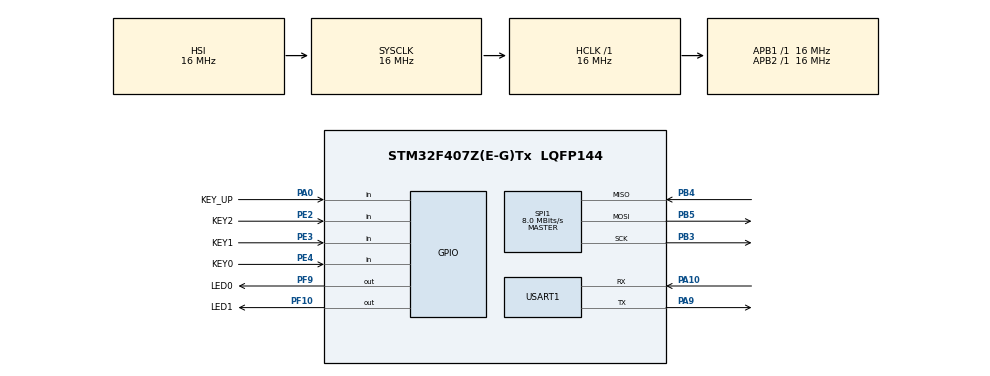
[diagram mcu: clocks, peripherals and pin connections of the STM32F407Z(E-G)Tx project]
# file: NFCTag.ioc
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Mcu.Family=STM32F4
Mcu.Name=STM32F407Z(E-G)Tx
Mcu.Package=LQFP144
NVIC.PriorityGroup=NVIC_PRIORITYGROUP_4
PA0-WKUP.GPIO_Label=KEY_UP
PA0-WKUP.GPIO_PuPd=GPIO_PULLDOWN
PA0-WKUP.Signal=GPIO_Input
PA10.Mode=Asynchronous
PA10.Signal=USART1_RX
PA9.Mode=Asynchronous
PA9.Signal=USART1_TX
PB3.Mode=Full_Duplex_Master
PB3.Signal=SPI1_SCK
PB4.Mode=Full_Duplex_Master
PB4.Signal=SPI1_MISO
PB5.Mode=Full_Duplex_Master
PB5.Signal=SPI1_MOSI
PE2.GPIO_Label=KEY2
PE2.GPIO_PuPd=GPIO_PULLUP
PE2.Signal=GPIO_Input
PE3.GPIO_Label=KEY1
PE3.GPIO_PuPd=GPIO_PULLUP
PE3.Signal=GPIO_Input
PE4.GPIO_Label=KEY0
PE4.GPIO_PuPd=GPIO_PULLUP
PE4.Signal=GPIO_Input
PF10.GPIO_Label=LED1
PF10.GPIO_ModeDefaultOutputPP=GPIO_MODE_OUTPUT_PP
PF10.GPIO_PuPd=GPIO_PULLUP
PF10.GPIO_Speed=GPIO_SPEED_FREQ_HIGH
PF10.PinState=GPIO_PIN_SET
PF10.Signal=GPIO_Output
PF9.GPIO_Label=LED0
PF9.GPIO_PuPd=GPIO_PULLUP
PF9.GPIO_Speed=GPIO_SPEED_FREQ_HIGH
PF9.PinState=GPIO_PIN_SET
PF9.Signal=GPIO_Output
ProjectManager.HeapSize=0x200
ProjectManager.StackSize=0x400
ProjectManager.TargetToolchain=MDK-ARM V5.27
RCC.AHBFreq_Value=16000000
RCC.APB1Freq_Value=16000000
RCC.APB2Freq_Value=16000000
RCC.CortexFreq_Value=16000000
RCC.HSE_VALUE=25000000
RCC.HSI_VALUE=16000000
RCC.LSE_VALUE=32768
RCC.SYSCLKFreq_VALUE=16000000
RCC.VCOOutputFreq_Value=192000000
SPI1.CalculateBaudRate=8.0 MBits/s
SPI1.Direction=SPI_DIRECTION_2LINES
SPI1.Mode=SPI_MODE_MASTER
SPI1.VirtualType=VM_MASTER
USART1.VirtualMode=VM_ASYNC
board=custom

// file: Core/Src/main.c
/* USER CODE BEGIN Header */
/**
  ******************************************************************************
  * @file           : main.c
  * @brief          : Main program body
  ******************************************************************************
  * @attention
  *
  * <h2><center>&copy; Copyright (c) 2021 STMicroelectronics.
  * All rights reserved.</center></h2>
  *
  * This software component is licensed by ST under BSD 3-Clause license,
  * the "License"; You may not use this file except in compliance with the
  * License. You may obtain a copy of the License at:
  *                        opensource.org/licenses/BSD-3-Clause
  *
  ******************************************************************************
  */
/* USER CODE END Header */
#include "main.h"
#include "spi.h"
#include "usart.h"
#include "gpio.h"
#include "key.h"
#include "MFRC522.h"
#include <string.h>

void SystemClock_Config(void);

int main(void)
{
  /* USER CODE BEGIN 1 */
	uint8_t sta = 0, codigo = 0;
	uint16_t i, j;
	uint8_t cardstr[17], str[17];
	uint8_t sectorX_KeyA[] = {0xFF, 0xFF, 0xFF, 0xFF, 0xFF, 0xFF};
	uint8_t escribir[]="DatosDesdeMexico";
  /* USER CODE END 1 */

  /* MCU Configuration--------------------------------------------------------*/

  /* Reset of all peripherals, Initializes the Flash interface and the Systick. */
  HAL_Init();

  /* Configure the system clock */
  SystemClock_Config();

  /* Initialize all configured peripherals */
  MX_GPIO_Init();
  MX_USART1_UART_Init();
  MX_SPI1_Init();
  /* USER CODE BEGIN 2 */

  HAL_GPIO_WritePin(RC522_Rst_GPIO_Port, RC522_Rst_Pin, GPIO_PIN_SET);
  HAL_Delay(100);
  MFRC522_Init();
	sta = Read_MFRC522(VersionReg);
	printf("MFRC522 version: %x\r\n", sta);
	HAL_Delay(1000);
  /* USER CODE END 2 */

  /* Infinite loop */
  while (1) {
		memset(cardstr, 0, sizeof(cardstr));
		sta = MFRC522_Request(PICC_REQIDL, cardstr);
		if(sta == MI_OK) {
			HAL_GPIO_TogglePin(GPIOF, GPIO_PIN_9);
			printf("Card: %x,%x,%x\r\n", cardstr[0], cardstr[1], cardstr[2]);
			HAL_Delay(1);
			sta = MFRC522_Anticoll(cardstr);
			if(sta == MI_OK) {
				printf("UID: %x %x %x %x\r\n", cardstr[0], cardstr[1], cardstr[2], cardstr[3]);
				HAL_Delay(1);
				sta = MFRC522_SelectTag(cardstr);
				if(sta > 0) {
					codigo = KeyScan(1);
					switch(codigo) {
						case 1: //key0, read
							HAL_GPIO_TogglePin(GPIOF, GPIO_PIN_10);
							HAL_Delay(1);
							sta = MFRC522_Auth(0x60, 0, sectorX_KeyA, cardstr);	//sector 0
							printf("Authentication completed with status code %x\r\n", sta);
							for(i = 0; i < 16; i++) {
								for(j = i*4; j < (i+1)*4; j++) {
									sta = MFRC522_Read(j, str);
									printf("Cluster %d, Status = %d, ReadString=%s\r\n", j, sta, str);
								}
							}
							MFRC522_Halt();
							HAL_Delay(1);
							break;
						case 2: //key1, write
							HAL_GPIO_TogglePin(GPIOF, GPIO_PIN_9);
							HAL_GPIO_TogglePin(GPIOF, GPIO_PIN_10);
							HAL_Delay(1);
							sta = MFRC522_Auth(0x60,4,sectorX_KeyA, cardstr);	//sector 1
							if(sta == MI_OK) {
								sta = MFRC522_Write(4, escribir);
								printf("Write completed with status code %x\r\n", sta);
							}
							MFRC522_Halt();
							HAL_Delay(1);
							break;
						default:
							printf("Invalid key pressed down!\r\n");
							break;
					}
				}
			}
		}
  }
}

void SystemClock_Config(void)
{
  RCC_OscInitTypeDef RCC_OscInitStruct = {0};
  RCC_ClkInitTypeDef RCC_ClkInitStruct = {0};

  /** Configure the main internal regulator output voltage
  */
  __HAL_RCC_PWR_CLK_ENABLE();
  __HAL_PWR_VOLTAGESCALING_CONFIG(PWR_REGULATOR_VOLTAGE_SCALE1);
  /** Initializes the RCC Oscillators according to the specified parameters
  * in the RCC_OscInitTypeDef structure.
  */
  RCC_OscInitStruct.OscillatorType = RCC_OSCILLATORTYPE_HSI;
  RCC_OscInitStruct.HSIState = RCC_HSI_ON;
  RCC_OscInitStruct.HSICalibrationValue = RCC_HSICALIBRATION_DEFAULT;
  RCC_OscInitStruct.PLL.PLLState = RCC_PLL_NONE;
  if (HAL_RCC_OscConfig(&RCC_OscInitStruct) != HAL_OK)
  {
    Error_Handler();
  }
  /** Initializes the CPU, AHB and APB buses clocks
  */
  RCC_ClkInitStruct.ClockType = RCC_CLOCKTYPE_HCLK|RCC_CLOCKTYPE_SYSCLK
                              |RCC_CLOCKTYPE_PCLK1|RCC_CLOCKTYPE_PCLK2;
  RCC_ClkInitStruct.SYSCLKSource = RCC_SYSCLKSOURCE_HSI;
  RCC_ClkInitStruct.AHBCLKDivider = RCC_SYSCLK_DIV1;
  RCC_ClkInitStruct.APB1CLKDivider = RCC_HCLK_DIV1;
  RCC_ClkInitStruct.APB2CLKDivider = RCC_HCLK_DIV1;

  if (HAL_RCC_ClockConfig(&RCC_ClkInitStruct, FLASH_LATENCY_0) != HAL_OK)
  {
    Error_Handler();
  }
}

void Error_Handler(void)
{
  __disable_irq();
  while (1)
  {
  }
}

/************************ (C) COPYRIGHT STMicroelectronics *****END OF FILE****/
